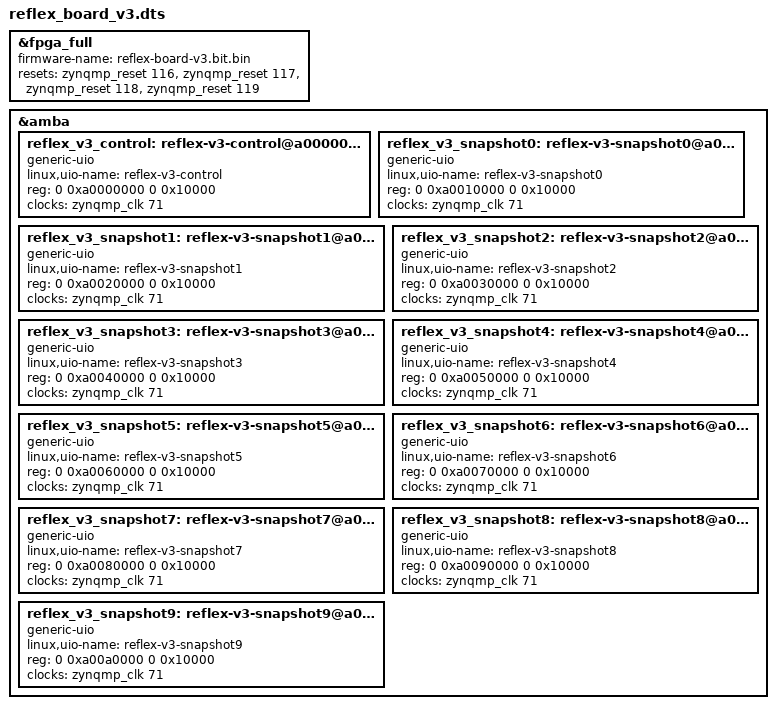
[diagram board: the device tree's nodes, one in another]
/dts-v1/;
/plugin/;
/ {
    fragment@0 {
        target = <&fpga_full>;
        __overlay__ {
            #address-cells = <2>;
            #size-cells = <2>;
            firmware-name = "reflex-board-v3.bit.bin";
            resets = <&zynqmp_reset 116>, <&zynqmp_reset 117>, <&zynqmp_reset 118>, <&zynqmp_reset 119>;
        };
    };
    fragment@1 {
        target = <&amba>;
        __overlay__ {
            #address-cells = <2>;
            #size-cells = <2>;
            reflex_v3_control: reflex-v3-control@a0000000 {
                compatible = "generic-uio";
                linux,uio-name = "reflex-v3-control";
                reg = <0 0xa0000000 0 0x10000>;
                clocks = <&zynqmp_clk 71>;
                status = "okay";
            };
            reflex_v3_snapshot0: reflex-v3-snapshot0@a0010000 {
                compatible = "generic-uio";
                linux,uio-name = "reflex-v3-snapshot0";
                reg = <0 0xa0010000 0 0x10000>;
                clocks = <&zynqmp_clk 71>;
                status = "okay";
            };
            reflex_v3_snapshot1: reflex-v3-snapshot1@a0020000 {
                compatible = "generic-uio";
                linux,uio-name = "reflex-v3-snapshot1";
                reg = <0 0xa0020000 0 0x10000>;
                clocks = <&zynqmp_clk 71>;
                status = "okay";
            };
            reflex_v3_snapshot2: reflex-v3-snapshot2@a0030000 {
                compatible = "generic-uio";
                linux,uio-name = "reflex-v3-snapshot2";
                reg = <0 0xa0030000 0 0x10000>;
                clocks = <&zynqmp_clk 71>;
                status = "okay";
            };
            reflex_v3_snapshot3: reflex-v3-snapshot3@a0040000 {
                compatible = "generic-uio";
                linux,uio-name = "reflex-v3-snapshot3";
                reg = <0 0xa0040000 0 0x10000>;
                clocks = <&zynqmp_clk 71>;
                status = "okay";
            };
            reflex_v3_snapshot4: reflex-v3-snapshot4@a0050000 {
                compatible = "generic-uio";
                linux,uio-name = "reflex-v3-snapshot4";
                reg = <0 0xa0050000 0 0x10000>;
                clocks = <&zynqmp_clk 71>;
                status = "okay";
            };
            reflex_v3_snapshot5: reflex-v3-snapshot5@a0060000 {
                compatible = "generic-uio";
                linux,uio-name = "reflex-v3-snapshot5";
                reg = <0 0xa0060000 0 0x10000>;
                clocks = <&zynqmp_clk 71>;
                status = "okay";
            };
            reflex_v3_snapshot6: reflex-v3-snapshot6@a0070000 {
                compatible = "generic-uio";
                linux,uio-name = "reflex-v3-snapshot6";
                reg = <0 0xa0070000 0 0x10000>;
                clocks = <&zynqmp_clk 71>;
                status = "okay";
            };
            reflex_v3_snapshot7: reflex-v3-snapshot7@a0080000 {
                compatible = "generic-uio";
                linux,uio-name = "reflex-v3-snapshot7";
                reg = <0 0xa0080000 0 0x10000>;
                clocks = <&zynqmp_clk 71>;
                status = "okay";
            };
            reflex_v3_snapshot8: reflex-v3-snapshot8@a0090000 {
                compatible = "generic-uio";
                linux,uio-name = "reflex-v3-snapshot8";
                reg = <0 0xa0090000 0 0x10000>;
                clocks = <&zynqmp_clk 71>;
                status = "okay";
            };
            reflex_v3_snapshot9: reflex-v3-snapshot9@a00a0000 {
                compatible = "generic-uio";
                linux,uio-name = "reflex-v3-snapshot9";
                reg = <0 0xa00a0000 0 0x10000>;
                clocks = <&zynqmp_clk 71>;
                status = "okay";
            };
        };
    };
};
